# NSUC1602 register map
Vendor: ARM Ltd.; Series: NSUC1602; File version: 0.0
CPU: CM3 r1p0, little endian, MPU, no FPU, 3 interrupt priority bits
Registers are 32-bit, read-write, reset 0x0 unless marked. A register's access mark holds for its fields unless they carry their own. Offsets are from the block's base; [hi:lo] are bit positions.

## PWMIO — S/T bus
Base 0x40004000
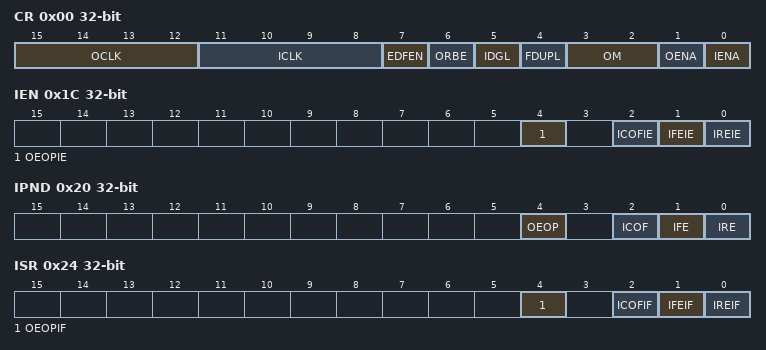
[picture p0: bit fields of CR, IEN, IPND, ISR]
0x00 CR (reset mask 0x1337F7F) — PWMIO控制寄存器
  [15:12] OCLK, [11:8] ICLK, [7] EDFEN, [6] ORBE, [5] IDGL, [4] FDUPL, [3:2] OM, [1] OENA, [0] IENA
0x04 IHT (reset mask 0x1337F7F) — 输入PWM高电平时间寄存器
  [13:0] IHT ro
0x08 ILT (reset mask 0x1337F7F) — 输入PWM低电平时间寄存器
  [13:0] ILT ro
0x0C ICNT (reset mask 0x1337F7F) — 输入PWM低电平计数器寄存器
  [13:0] ICNT ro
0x10 OPT (reset mask 0x1337F7F) — 输出PWM周期时间寄存器
  [13:0] OPT
0x14 OLT (reset mask 0x1337F7F) — 输出PWM低电平时间寄存器
  [13:0] OLT
0x18 OCNT (reset mask 0x1337F7F) — 输出PWM定时器数值寄存器
  [13:0] OCNT ro
0x1C IEN — 中断使能寄存器
  [4] OEOPIE, [2] ICOFIE, [1] IFEIE, [0] IREIE
0x20 IPND — 中断置起寄存器
  [4] OEOP, [2] ICOF, [1] IFE, [0] IRE
0x24 ISR — 中断使能置起寄存器
  [4] OEOPIF, [2] ICOFIF, [1] IFEIF, [0] IREIF

## TIM0 — S/T bus
Base 0x40005000
Same registers: TIM1 0x40006000
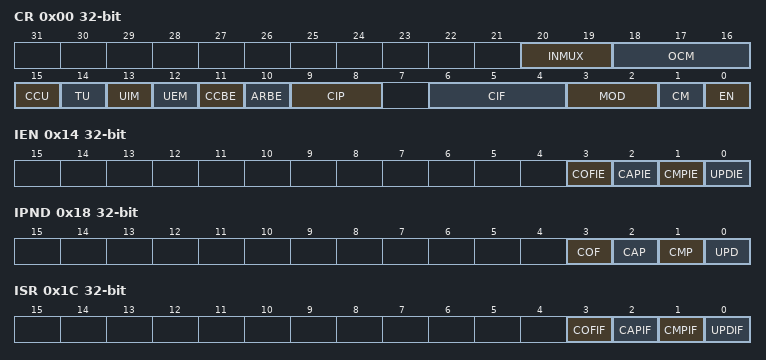
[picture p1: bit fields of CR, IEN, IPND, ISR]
0x00 CR (reset mask 0x1337F7F) — 定时器控制寄存器
  [20:19] INMUX, [18:16] OCM, [15] CCU wo, [14] TU wo, [13] UIM, [12] UEM, [11] CCBE, [10] ARBE, [9:8] CIP, [6:4] CIF, [3:2] MOD, [1] CM, [0] EN
0x04 CNT (reset mask 0x1337F7F) — 定时器计数器数值寄存器
  [15:0] CNT
0x08 PS (reset mask 0x1337F7F) — 定时器预分频寄存器
  [15:0] PS
0x0C AR (reset mask 0x1337F7F) — 定时器自动加载寄存器
  [15:0] AR
0x10 CC (reset mask 0x1337F7F) — 捕获比较寄存器
  [15:0] CC
0x14 IEN — 中断使能寄存器
  [3] COFIE, [2] CAPIE, [1] CMPIE, [0] UPDIE
0x18 IPND — 中断置起寄存器
  [3] COF, [2] CAP, [1] CMP, [0] UPD
0x1C ISR — 中断使能置起寄存器
  [3] COFIF, [2] CAPIF, [1] CMPIF, [0] UPDIF

## WWDG — S/T bus
Base 0x40007000
0x00 WCKSEL — WWDG唤醒时钟选择寄存器
  [2:0] WCKSEL
0x04 CKSEL — WWDG计数器时钟选择寄存器
  [2:0] CKSEL
0x08 TWIN (reset mask 0x1337F7F) — 触发窗口寄存器
  [7:0] TWIN
0x0C TRG (reset mask 0x1337F7F) — 触发寄存器寄存器
  [7:0] TRG
0x10 CNT (reset mask 0x1337F7F) — WWDG 计数器数值寄存器
  [7:0] CNT ro
0x14 INTCNT — 提前中断窗口寄存器
  [3:0] INTR
0x18 IEN — WWDG看门狗中断使能
  [0] AHIE
0x1C ISR — 中断状态寄存器
  [0] AHIF

## DWDG — S/T bus
Base 0x40008000
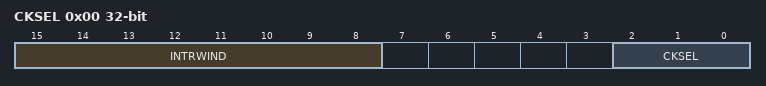
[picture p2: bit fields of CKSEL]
0x00 CKSEL (reset mask 0x1337F7F) — DWDG时钟选择寄存器
  [15:8] INTRWIND, [2:0] CKSEL
0x04 RR (reset mask 0x1337F7F) — DWDG加载寄存器
  [15:0] RR
0x08 TRG (reset mask 0x1337F7F) — DWDG触发寄存器
  [7:0] TRG
0x0C CNT (reset mask 0x1337F7F) — DWDG计数器数值寄存器
  [15:0] CNT ro
0x10 IEN — 中断使能寄存器
  [0] AHIE
0x14 ISR — 中断状态寄存器
  [0] AHIF

## SSI — S/T bus
Base 0x4000A000
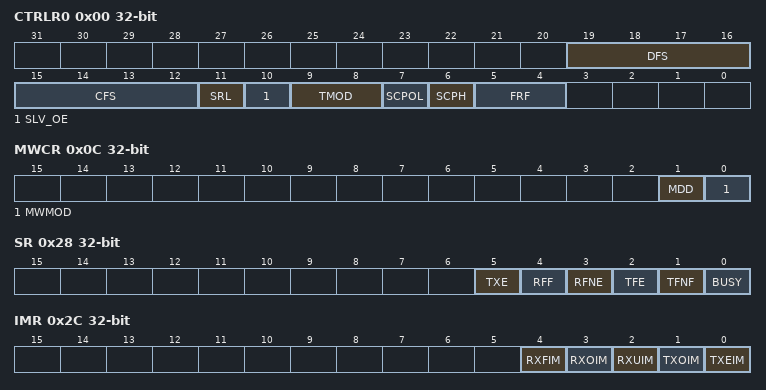
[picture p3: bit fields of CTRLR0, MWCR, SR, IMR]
0x00 CTRLR0 (reset mask 0x1337F7F) — Control Register 0 ,Width:16 bits
  [19:16] DFS, [15:12] CFS, [11] SRL, [10] SLV_OE, [9:8] TMOD, [7] SCPOL, [6] SCPH, [5:4] FRF
0x08 SSIENR — SSI Enable Register
  [0] SSI_EN
0x0C MWCR — Microwire Control Register
  [1] MDD, [0] MWMOD
0x18 TXFTLR — Transmit FIFO Threshold Level
  [1:0] TFT
0x1C RXFTLR — Receive FIFO Threshold Level
  [1:0] RFT
0x20 TXFLR — Transmit FIFO Level Register
  [2:0] TXFLR ro
0x24 RXFLR — Receive FIFO Level Register
  [2:0] RXFLR ro
0x28 SR — Status Register
  [5] TXE ro, [4] RFF ro, [3] RFNE ro, [2] TFE ro, [1] TFNF ro, [0] BUSY ro
0x2C IMR — Interrupt Mask Register
  [4] RXFIM, [3] RXOIM, [2] RXUIM, [1] TXOIM, [0] TXEIM
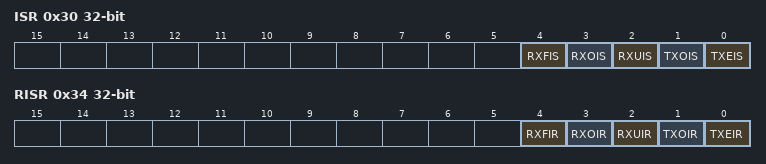
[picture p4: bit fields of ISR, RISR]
0x30 ISR — Interrupt Status Register
  [4] RXFIS ro, [3] RXOIS ro, [2] RXUIS ro, [1] TXOIS ro, [0] TXEIS ro
0x34 RISR — Raw Interrupt Status Register
  [4] RXFIR ro, [3] RXOIR ro, [2] RXUIR ro, [1] TXOIR ro, [0] TXEIR ro
0x38 TXOICR — Transmit FIFO Overflow Interrupt Clear Register
  [0] TXOICR ro
0x3C RXOICR — Receive FIFO Overflow Interrupt Clear Register
  [0] RXOICR ro
0x40 RXUICR — Receive FIFO Underflow Interrupt Clear Register
  [0] RXUICR ro
0x48 ICR — Interrupt Clear Register
  [0] ICR ro
0x58 IDR (reset mask 0x1337F7F) — Identification Register
  [31:0] IDCODE ro
0x5C SSI_COMP_VERSION (reset mask 0x1337F7F) — coreKit version ID register
  [31:0] SSI_COMP_VERSION ro
0x60 DR (reset mask 0x1337F7F) — Data Register.Width:32-bits, When the register is read, data in the receive FIFO buffer is accessed. When it is written to, data are moved into the transmit FIFO buffer; a write can occur only when SSI_EN = 1. FIFOs are reset when SSI_EN = 0.地址范围0x60~0x64，对应FIFO深度为2
